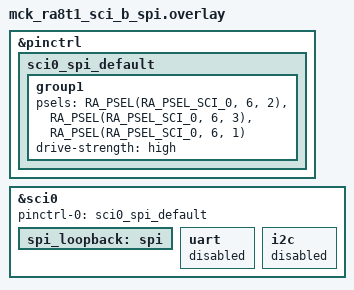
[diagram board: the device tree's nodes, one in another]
/*
 * Copyright (c) 2025 Renesas Electronics Corporation
 * SPDX-License-Identifier: Apache-2.0
 */

#define SPI_LOOPBACK_SLOW_HZ 1000000
#define SPI_LOOPBACK_FAST_HZ 2500000

&pinctrl {
	sci0_spi_default: sci0_spi_default {
		group1 {
			/* MISO MOSI SCK */
			psels = <RA_PSEL(RA_PSEL_SCI_0, 6, 2)>,
				<RA_PSEL(RA_PSEL_SCI_0, 6, 3)>,
				<RA_PSEL(RA_PSEL_SCI_0, 6, 1)>;
			drive-strength = "high";
		};
	};
};

&sci0 {
	pinctrl-0 = <&sci0_spi_default>;
	pinctrl-names = "default";

	spi_loopback: spi {
		status = "okay";
	};

	uart {
		status = "disabled";
	};

	i2c {
		status = "disabled";
	};
};

#include "../spi-loopback.dtsi"
